# CC1312PSIP register map
File version: 1.0
CPU: CM4 1.0, other endian, MPU, FPU, 3 interrupt priority bits
Registers are 32-bit, read-write, reset 0x0 unless marked. A register's access mark holds for its fields unless they carry their own. Offsets are from the block's base; [hi:lo] are bit positions; 'fields as' and 'values as' point back to an identical list.

## I2S0 — I2S Audio DMA module supporting formats I2S, LJF, RJF and DSP
Base 0x40021000
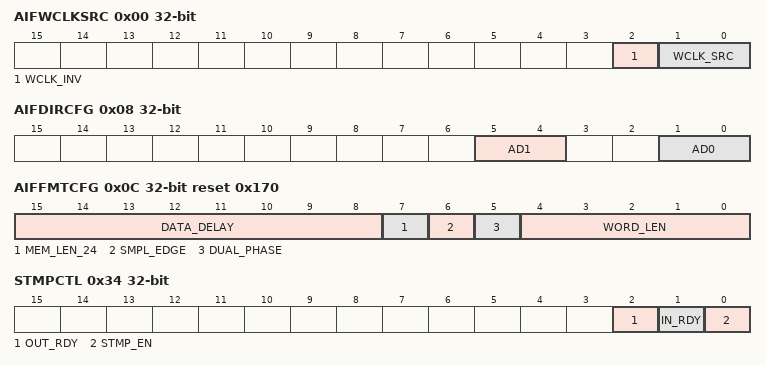
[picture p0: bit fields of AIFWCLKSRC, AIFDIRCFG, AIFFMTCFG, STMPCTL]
0x00 AIFWCLKSRC — WCLK Source Selection
  [2] WCLK_INV — [2:2] Inverts WCLK source (pad or internal) when set. 0: Not inverted 1: Inverted
  [1:0] WCLK_SRC — [1:0] Selects WCLK source for AIF (should be the same as the BCLK source). The BCLK source is defined in the PRCM:I2SBCLKSEL.SRC
    3=RESERVED (Not supported. Will give same WCLK as 'NONE' ('00')); 2=INT (Internal WCLK generator, from module PRCM); 1=EXT (External WCLK generator, from pad); 0=NONE (None ('0'))
0x04 AIFDMACFG — DMA Buffer Size Configuration
  [7:0] END_FRAME_IDX — [7:0] Defines the length of the DMA buffer. Writing a non-zero value to this register field enables and initializes AIF. Note that before doing so, all other configuration must have been done, and AIFINPTRNEXT/AIFOUTPTRNEXT must have been loaded.
0x08 AIFDIRCFG — Pin Direction
  [5:4] AD1 — [5:4] Configures the AD1 audio data pin usage: 0x3: Reserved
    2=OUT (Output mode); 1=IN (Input mode); 0=DIS (Not in use (disabled))
  [1:0] AD0 — [1:0] Configures the AD0 audio data pin usage: 0x3: Reserved
    values as AD1
0x0C AIFFMTCFG reset 0x170 — Serial Interface Format Configuration
  [15:8] DATA_DELAY — [15:8] The number of BCLK periods between a WCLK edge and MSB of the first word in a phase: 0x00: LJF and DSP format 0x01: I2S and DSP format 0x02: RJF format ... 0xFF: RJF format Note: When 0, MSB of the next word will be output in the idle period between LSB of the previous word and the start of the next word. Otherwise logical 0 will be output until the data delay has expired.
  [7] MEM_LEN_24 — [7:7] The size of each word stored to or loaded from memory:
    1=24BIT (24-bit (one 8 bit and one 16 bit locked access per sample)); 0=16BIT (16-bit (one 16 bit access per sample))
  [6] SMPL_EDGE — [6:6] On the serial audio interface, data (and wclk) is sampled and clocked out on opposite edges of BCLK.
    1=POS (Data is sampled on the positive edge and clocked out on the negative edge.); 0=NEG (Data is sampled on the negative edge and clocked out on the positive edge.)
  [5] DUAL_PHASE — [5:5] Selects dual- or single-phase format. 0: Single-phase: DSP format 1: Dual-phase: I2S, LJF and RJF formats
  [4:0] WORD_LEN — [4:0] Number of bits per word (8-24): In single-phase format, this is the exact number of bits per word. In dual-phase format, this is the maximum number of bits per word. Values below 8 and above 24 give undefined behavior. Data written to memory is always aligned to 16 or 24 bits as defined by MEM_LEN_24. Bit widths that differ from this alignment will either be truncated or zero padded.
0x10 AIFWMASK0 reset 0x3 — Word Selection Bit Mask for Pin 0
  [7:0] MASK — [7:0] Bit-mask indicating valid channels in a frame on AD0. In single-phase mode, each bit represents one channel, starting with LSB for the first word in the frame. A frame can contain up to 8 channels. Channels that are not included in the mask will not be sampled and stored in memory, and clocked out as '0'. In dual-phase mode, only the two LSBs are considered. For a stereo configuration, set both bits. For a mono configuration, set bit 0 only. In mono mode, only channel 0 will be sampled and stored to memory, and channel 0 will be repeated when clocked out. In mono mode, only channel 0 will be sampled and stored to memory, and channel 0 will be repeated in the second phase when clocked out. If all bits are zero, no input words will be stored to memory, and the output data lines will be constant '0'. This can be utilized when PWM debug output is desired without any actively used output pins.
0x14 AIFWMASK1 reset 0x3 — Word Selection Bit Mask for Pin 1
  [7:0] MASK — [7:0] Bit-mask indicating valid channels in a frame on AD1. In single-phase mode, each bit represents one channel, starting with LSB for the first word in the frame. A frame can contain up to 8 channels. Channels that are not included in the mask will not be sampled and stored in memory, and clocked out as '0'. In dual-phase mode, only the two LSBs are considered. For a stereo configuration, set both bits. For a mono configuration, set bit 0 only. In mono mode, only channel 0 will be sampled and stored to memory, and channel 0 will be repeated when clocked out. In mono mode, only channel 0 will be sampled and stored to memory, and channel 0 will be repeated in the second phase when clocked out. If all bits are zero, no input words will be stored to memory, and the output data lines will be constant '0'. This can be utilized when PWM debug output is desired without any actively used output pins.
0x18 AIFWMASK2 — Internal. Only to be used through TI provided API.
  [31:0] RESERVED0 ro — [31:0] Internal. Only to be used through TI provided API.
0x1C AIFPWMVALUE — Audio Interface PWM Debug Value
  [15:0] PULSE_WIDTH — [15:0] The value written to this register determines the width of the active high PWM pulse (pwm_debug), which starts together with MSB of the first output word in a DMA buffer: 0x0000: Constant low 0x0001: Width of the pulse (number of BCLK cycles, here 1). ... 0xFFFE: Width of the pulse (number of BCLK cycles, here 65534). 0xFFFF: Constant high
0x20 AIFINPTRNEXT — DMA Input Buffer Next Pointer
  [31:0] PTR — [31:0] Pointer to the first byte in the next DMA input buffer. The read value equals the last written value until the currently used DMA input buffer is completed, and then becomes null when the last written value is transferred to the DMA controller to start on the next buffer. This event is signalized by IRQFLAGS.AIF_DMA_IN. At startup, the value must be written once before and once after configuring the DMA buffer size in AIFDMACFG. The next pointer must be written to this register while the DMA function uses the previously written pointer. If not written in time, IRQFLAGS.PTR_ERR will be raised and all input pins will be disabled.
0x24 AIFINPTR — DMA Input Buffer Current Pointer
  [31:0] PTR ro — [31:0] Value of the DMA input buffer pointer currently used by the DMA controller. Incremented by 1 (byte) or 2 (word) for each AHB access.
0x28 AIFOUTPTRNEXT — DMA Output Buffer Next Pointer
  [31:0] PTR — [31:0] Pointer to the first byte in the next DMA output buffer. The read value equals the last written value until the currently used DMA output buffer is completed, and then becomes null when the last written value is transferred to the DMA controller to start on the next buffer. This event is signalized by IRQFLAGS.AIF_DMA_OUT. At startup, the value must be written once before and once after configuring the DMA buffer size in AIFDMACFG. At this time, the first two samples will be fetched from memory. The next pointer must be written to this register while the DMA function uses the previously written pointer. If not written in time, IRQFLAGS.PTR_ERR will be raised and all output pins will be disabled.
0x2C AIFOUTPTR — DMA Output Buffer Current Pointer
  [31:0] PTR ro — [31:0] Value of the DMA output buffer pointer currently used by the DMA controller Incremented by 1 (byte) or 2 (word) for each AHB access.
0x34 STMPCTL — Samplestamp Generator Control Register
  [2] OUT_RDY ro — [2:2] Low until the output pins are ready to be started by the samplestamp generator. When started (that is STMPOUTTRIG equals the WCLK counter) the bit goes back low.
  [1] IN_RDY ro — [1:1] Low until the input pins are ready to be started by the samplestamp generator. When started (that is STMPINTRIG equals the WCLK counter) the bit goes back low.
  [0] STMP_EN — [0:0] Enables the samplestamp generator. The samplestamp generator must only be enabled after it has been properly configured. When cleared, all samplestamp generator counters and capture values are cleared.
0x38 STMPXCNTCAPT0 — Captured XOSC Counter Value, Capture Channel 0
  [15:0] CAPT_VALUE ro — [15:0] The value of the samplestamp XOSC counter (STMPXCNT.CURR_VALUE) last time an event was pulsed (event source selected in [EVENT.I2SSTMPSEL0.EV] for channel 0). This number corresponds to the number of 24 MHz clock cycles since the last positive edge of the selected WCLK. The value is cleared when STMPCTL.STMP_EN = 0. Note: Due to buffering and synchronization, WCLK is delayed by a small number of BCLK periods and clk periods. Note: When calculating the fractional part of the sample stamp, STMPXPER may be less than this bit field.
0x3C STMPXPER — XOSC Period Value
  [15:0] VALUE ro — [15:0] The number of 24 MHz clock cycles in the previous WCLK period (that is - the next value of the XOSC counter at the positive WCLK edge, had it not been reset to 0). The value is cleared when STMPCTL.STMP_EN = 0.
0x40 STMPWCNTCAPT0 — Captured WCLK Counter Value, Capture Channel 0
  [15:0] CAPT_VALUE ro — [15:0] The value of the samplestamp WCLK counter (STMPWCNT.CURR_VALUE) last time an event was pulsed (event source selected in EVENT:I2SSTMPSEL0.EV for channel 0). This number corresponds to the number of positive WCLK edges since the samplestamp generator was enabled (not taking modification through STMPWADD/STMPWSET into account). The value is cleared when STMPCTL.STMP_EN = 0.
0x44 STMPWPER — WCLK Counter Period Value
  [15:0] VALUE — [15:0] Used to define when STMPWCNT is to be reset so number of WCLK edges are found for the size of the sample buffer. This is thus a modulo value for the WCLK counter. This number must correspond to the size of the sample buffer used by the system (that is the index of the last sample plus 1).
0x48 STMPINTRIG — WCLK Counter Trigger Value for Input Pins
  [15:0] IN_START_WCNT — [15:0] Compare value used to start the incoming audio streams. This bit field shall equal the WCLK counter value during the WCLK period in which the first input word(s) are sampled and stored to memory (that is the sample at the start of the very first DMA input buffer). The value of this register takes effect when the following conditions are met: - One or more pins are configured as inputs in AIFDIRCFG. - AIFDMACFG has been configured for the correct buffer size, and at least 32 BCLK cycle ticks have happened. Note: To avoid false triggers, this bit field should be set higher than STMPWPER.VALUE.
0x4C STMPOUTTRIG — WCLK Counter Trigger Value for Output Pins
  [15:0] OUT_START_WCNT — [15:0] Compare value used to start the outgoing audio streams. This bit field must equal the WCLK counter value during the WCLK period in which the first output word(s) read from memory are clocked out (that is the sample at the start of the very first DMA output buffer). The value of this register takes effect when the following conditions are met: - One or more pins are configured as outputs in AIFDIRCFG. - AIFDMACFG has been configured for the correct buffer size, and 32 BCLK cycle ticks have happened. - 2 samples have been preloaded from memory (examine the AIFOUTPTR register if necessary). Note: The memory read access is only performed when required, that is channels 0/1 must be selected in AIFWMASK0/AIFWMASK1. Note: To avoid false triggers, this bit field should be set higher than STMPWPER.VALUE.
0x50 STMPWSET — WCLK Counter Set Operation
  [15:0] VALUE — [15:0] WCLK counter modification: Sets the running WCLK counter equal to the written value.
0x54 STMPWADD — WCLK Counter Add Operation
  [15:0] VALUE_INC — [15:0] WCLK counter modification: Adds the written value to the running WCLK counter. If a positive edge of WCLK occurs at the same time as the operation, this will be taken into account. To add a negative value, write "STMPWPER.VALUE - value".
0x58 STMPXPERMIN reset 0xFFFF — XOSC Minimum Period Value Minimum Value of STMPXPER
  [15:0] VALUE — [15:0] Each time STMPXPER is updated, the value is also loaded into this register, provided that the value is smaller than the current value in this register. When written, the register is reset to 0xFFFF (65535), regardless of the value written. The minimum value can be used to detect extra WCLK pulses (this registers value will be significantly smaller than STMPXPER.VALUE).
0x5C STMPWCNT — Current Value of WCNT
  [15:0] CURR_VALUE ro — [15:0] Current value of the WCLK counter
0x60 STMPXCNT — Current Value of XCNT
  [15:0] CURR_VALUE ro — [15:0] Current value of the XOSC counter, latched when reading STMPWCNT.
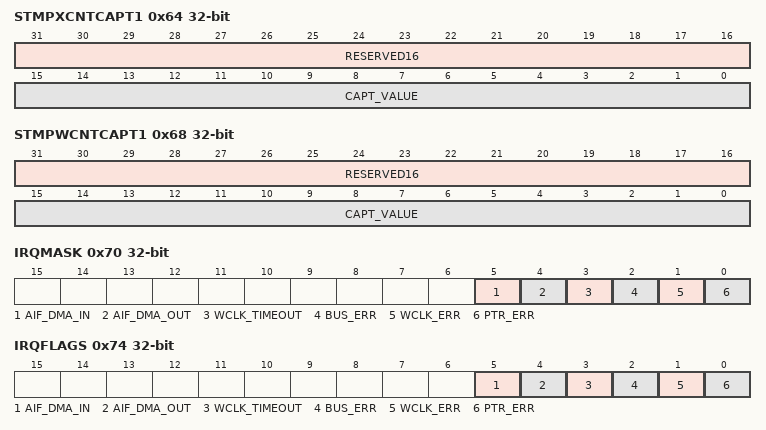
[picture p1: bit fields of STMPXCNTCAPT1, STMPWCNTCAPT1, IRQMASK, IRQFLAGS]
0x64 STMPXCNTCAPT1 — Internal. Only to be used through TI provided API.
  [31:16] RESERVED16 ro — [31:16] Internal. Only to be used through TI provided API.
  [15:0] CAPT_VALUE ro — [15:0] Internal. Only to be used through TI provided API.
0x68 STMPWCNTCAPT1 — Internal. Only to be used through TI provided API.
  fields as STMPXCNTCAPT1
0x70 IRQMASK — Interrupt Mask Register Selects mask states of the flags in IRQFLAGS that contribute to the I2S_IRQ event.
  [5] AIF_DMA_IN — [5:5] IRQFLAGS.AIF_DMA_IN interrupt mask 0: Disable 1: Enable
  [4] AIF_DMA_OUT — [4:4] IRQFLAGS.AIF_DMA_OUT interrupt mask 0: Disable 1: Enable
  [3] WCLK_TIMEOUT — [3:3] IRQFLAGS.WCLK_TIMEOUT interrupt mask 0: Disable 1: Enable
  [2] BUS_ERR — [2:2] IRQFLAGS.BUS_ERR interrupt mask 0: Disable 1: Enable
  [1] WCLK_ERR — [1:1] IRQFLAGS.WCLK_ERR interrupt mask 0: Disable 1: Enable
  [0] PTR_ERR — [0:0] IRQFLAGS.PTR_ERR interrupt mask. 0: Disable 1: Enable
0x74 IRQFLAGS — Raw Interrupt Status Register
  [5] AIF_DMA_IN ro — [5:5] Set when condition for this bit field event occurs (auto cleared when input pointer is updated - AIFINPTRNEXT), see description of AIFINPTRNEXT register for details.
  [4] AIF_DMA_OUT ro — [4:4] Set when condition for this bit field event occurs (auto cleared when output pointer is updated - AIFOUTPTRNEXT), see description of AIFOUTPTRNEXT register for details
  [3] WCLK_TIMEOUT ro — [3:3] Set when the sample stamp generator does not detect a positive WCLK edge for 65535 clk periods. This signalizes that the internal or external BCLK and WCLK generator source has been disabled. The bit is sticky and may only be cleared by software (by writing '1' to IRQCLR.WCLK_TIMEOUT).
  [2] BUS_ERR ro — [2:2] Set when a DMA operation is not completed in time (that is audio output buffer underflow, or audio input buffer overflow). This error requires a complete restart since word synchronization has been lost. The bit is sticky and may only be cleared by software (by writing '1' to IRQCLR.BUS_ERR). Note that DMA initiated transactions to illegal addresses will not trigger an interrupt. The response to such transactions is undefined.
  [1] WCLK_ERR ro — [1:1] Set when: - An unexpected WCLK edge occurs during the data delay period of a phase. Note unexpected WCLK edges during the word and idle periods of the phase are not detected. - In dual-phase mode, when two WCLK edges are less than 4 BCLK cycles apart. - In single-phase mode, when a WCLK pulse occurs before the last channel. This error requires a complete restart since word synchronization has been lost. The bit is sticky and may only be cleared by software (by writing '1' to IRQCLR.WCLK_ERR).
  [0] PTR_ERR ro — [0:0] Set when AIFINPTRNEXT or AIFOUTPTRNEXT has not been loaded with the next block address in time. This error requires a complete restart since word synchronization has been lost. The bit is sticky and may only be cleared by software (by writing '1' to IRQCLR.PTR_ERR).
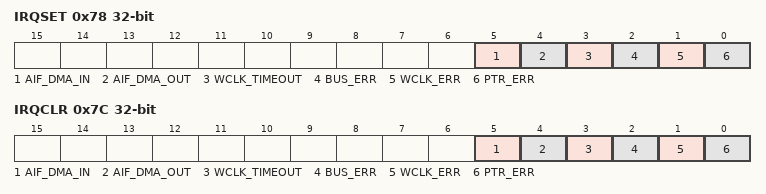
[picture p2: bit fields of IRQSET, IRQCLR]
0x78 IRQSET — Interrupt Set Register
  [5] AIF_DMA_IN wo — [5:5] 1: Sets the interrupt of IRQFLAGS.AIF_DMA_IN (unless a auto clear criteria was given at the same time, in which the set will be ignored)
  [4] AIF_DMA_OUT wo — [4:4] 1: Sets the interrupt of IRQFLAGS.AIF_DMA_OUT (unless a auto clear criteria was given at the same time, in which the set will be ignored)
  [3] WCLK_TIMEOUT wo — [3:3] 1: Sets the interrupt of IRQFLAGS.WCLK_TIMEOUT
  [2] BUS_ERR wo — [2:2] 1: Sets the interrupt of IRQFLAGS.BUS_ERR
  [1] WCLK_ERR wo — [1:1] 1: Sets the interrupt of IRQFLAGS.WCLK_ERR
  [0] PTR_ERR wo — [0:0] 1: Sets the interrupt of IRQFLAGS.PTR_ERR
0x7C IRQCLR — Interrupt Clear Register
  [5] AIF_DMA_IN wo — [5:5] 1: Clears the interrupt of IRQFLAGS.AIF_DMA_IN (unless a set criteria was given at the same time in which the clear will be ignored)
  [4] AIF_DMA_OUT wo — [4:4] 1: Clears the interrupt of IRQFLAGS.AIF_DMA_OUT (unless a set criteria was given at the same time in which the clear will be ignored)
  [3] WCLK_TIMEOUT wo — [3:3] 1: Clears the interrupt of IRQFLAGS.WCLK_TIMEOUT (unless a set criteria was given at the same time in which the clear will be ignored)
  [2] BUS_ERR wo — [2:2] 1: Clears the interrupt of IRQFLAGS.BUS_ERR (unless a set criteria was given at the same time in which the clear will be ignored)
  [1] WCLK_ERR wo — [1:1] 1: Clears the interrupt of IRQFLAGS.WCLK_ERR (unless a set criteria was given at the same time in which the clear will be ignored)
  [0] PTR_ERR wo — [0:0] 1: Clears the interrupt of IRQFLAGS.PTR_ERR (unless a set criteria was given at the same time in which the clear will be ignored)
